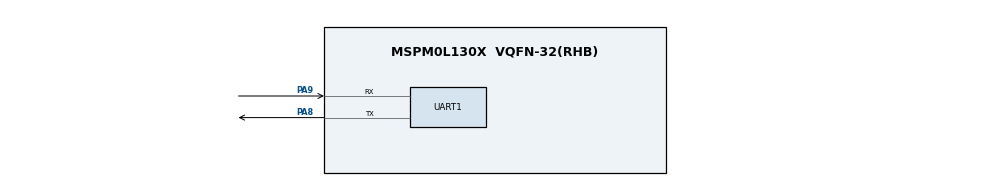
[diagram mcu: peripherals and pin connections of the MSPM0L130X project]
/**
 * @cliArgs --device "MSPM0L130X" --part "Default" --package "VQFN-32(RHB)" --product "mspm0_sdk@2.05.00.05"
 * @versions {"tool":"1.24.0+4110"}
 */

/**
 * Import the modules used in this configuration.
 */
const GPIO   = scripting.addModule("/ti/driverlib/GPIO", {}, false);
const GPIO1  = GPIO.addInstance();
const GPIO2  = GPIO.addInstance();
const SYSCTL = scripting.addModule("/ti/driverlib/SYSCTL");
const UART   = scripting.addModule("/ti/driverlib/UART", {}, false);
const UART1  = UART.addInstance();

/**
 * Write custom configuration values to the imported modules.
 */
GPIO1.$name                         = "GPIO_LEDS";
GPIO1.port                          = "PORTA";
GPIO1.associatedPins.create(3);
GPIO1.associatedPins[0].$name       = "USER_LED_1";
GPIO1.associatedPins[0].assignedPin = "13";
GPIO1.associatedPins[1].$name       = "USER_LED_2";
GPIO1.associatedPins[2].$name       = "USER_LED_3";

const Board = scripting.addModule("/ti/driverlib/Board", {}, false);

GPIO2.$name                         = "GPIO_TEST";
GPIO2.port                          = "PORTA";
GPIO2.associatedPins[0].$name       = "targetPin";
GPIO2.associatedPins[0].assignedPin = "12";

SYSCTL.clockTreeEn = true;

UART1.$name                    = "UART_0";
UART1.targetBaudRate           = 115200;
UART1.peripheral.rxPin.$assign = "PA9";
UART1.peripheral.txPin.$assign = "PA8";
UART1.txPinConfig.$name        = "ti_driverlib_gpio_GPIOPinGeneric0";
UART1.rxPinConfig.$name        = "ti_driverlib_gpio_GPIOPinGeneric1";

/**
 * Pinmux solution for unlocked pins/peripherals. This ensures that minor changes to the automatic solver in a future
 * version of the tool will not impact the pinmux you originally saw.  These lines can be completely deleted in order to
 * re-solve from scratch.
 */
GPIO1.associatedPins[0].pin.$suggestSolution = "PA13";
GPIO1.associatedPins[1].pin.$suggestSolution = "PA0";
GPIO1.associatedPins[2].pin.$suggestSolution = "PA1";
Board.peripheral.$suggestSolution            = "DEBUGSS";
Board.peripheral.swclkPin.$suggestSolution   = "PA20";
Board.peripheral.swdioPin.$suggestSolution   = "PA19";
GPIO2.associatedPins[0].pin.$suggestSolution = "PA12";
UART1.peripheral.$suggestSolution            = "UART0";
